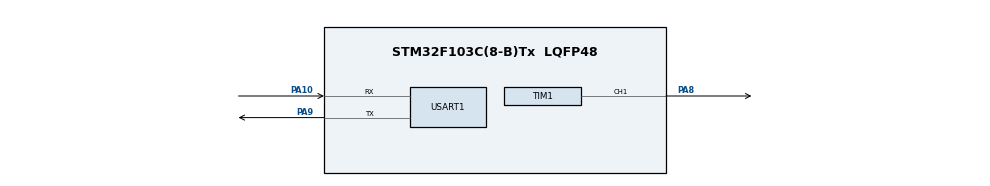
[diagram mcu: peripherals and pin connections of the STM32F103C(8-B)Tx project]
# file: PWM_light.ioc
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Mcu.Family=STM32F1
Mcu.Name=STM32F103C(8-B)Tx
Mcu.Package=LQFP48
NVIC.PriorityGroup=NVIC_PRIORITYGROUP_4
PA10.Mode=Asynchronous
PA10.Signal=USART1_RX
PA13.Mode=JTAG_4_pins
PA13.Signal=SYS_JTMS-SWDIO
PA14.Mode=JTAG_4_pins
PA14.Signal=SYS_JTCK-SWCLK
PA15.Mode=JTAG_4_pins
PA15.Signal=SYS_JTDI
PA8.Signal=S_TIM1_CH1
PA9.Mode=Asynchronous
PA9.Signal=USART1_TX
PB3.Mode=JTAG_4_pins
PB3.Signal=SYS_JTDO-TRACESWO
ProjectManager.HeapSize=0x200
ProjectManager.StackSize=0x400
ProjectManager.TargetToolchain=CMake
RCC.AHBCLKDivider=RCC_SYSCLK_DIV4
RCC.AHBFreq_Value=2000000
RCC.APB1Freq_Value=2000000
RCC.APB1TimFreq_Value=2000000
RCC.APB2Freq_Value=2000000
RCC.APB2TimFreq_Value=2000000
RCC.HCLKFreq_Value=2000000
RCC.USBFreq_Value=8000000
SH.S_TIM1_CH1.0=TIM1_CH1,PWM Generation1 CH1
TIM1.AutoReloadPreload=TIM_AUTORELOAD_PRELOAD_ENABLE
TIM1.Channel-PWM\ Generation1\ CH1=TIM_CHANNEL_1
TIM1.Period=40000
TIM1.Pulse-PWM\ Generation1\ CH1=30000
USART1.VirtualMode=VM_ASYNC
board=custom

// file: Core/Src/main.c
/* USER CODE BEGIN Header */
/**
  ******************************************************************************
  * @file           : main.c
  * @brief          : Main program body
  ******************************************************************************
  * @attention
  *
  * Copyright (c) 2026 STMicroelectronics.
  * All rights reserved.
  *
  * This software is licensed under terms that can be found in the LICENSE file
  * in the root directory of this software component.
  * If no LICENSE file comes with this software, it is provided AS-IS.
  *
  ******************************************************************************
  */
/* USER CODE END Header */
#include "main.h"
#include "tim.h"
#include "usart.h"
#include "gpio.h"

void SystemClock_Config(void);

int main(void)
{

  /* MCU Configuration--------------------------------------------------------*/

  /* Reset of all peripherals, Initializes the Flash interface and the Systick. */
  HAL_Init();

  /* Configure the system clock */
  SystemClock_Config();

  /* Initialize all configured peripherals */
  MX_GPIO_Init();
  MX_TIM1_Init();
  MX_USART1_UART_Init();
  /* USER CODE BEGIN 2 */
  HAL_TIM_PWM_Start(&htim1, TIM_CHANNEL_1);
  /* USER CODE END 2 */

  /* Infinite loop */
  /* USER CODE BEGIN WHILE */
  while (1)
  {
    for(int32_t duty=0;duty<=(int32_t)htim1.Init.Period;duty+=300)
    {
      __HAL_TIM_SET_COMPARE(&htim1,TIM_CHANNEL_1,duty);
      HAL_Delay(1);
    }
    for(int32_t duty=(int32_t)htim1.Init.Period;duty>=0;duty-=300)
    {
      __HAL_TIM_SET_COMPARE(&htim1,TIM_CHANNEL_1,duty);
      HAL_Delay(1);
    }
    /* USER CODE END WHILE */

  }
}

void SystemClock_Config(void)
{
  RCC_OscInitTypeDef RCC_OscInitStruct = {0};
  RCC_ClkInitTypeDef RCC_ClkInitStruct = {0};

  /** Initializes the RCC Oscillators according to the specified parameters
  * in the RCC_OscInitTypeDef structure.
  */
  RCC_OscInitStruct.OscillatorType = RCC_OSCILLATORTYPE_HSI;
  RCC_OscInitStruct.HSIState = RCC_HSI_ON;
  RCC_OscInitStruct.HSICalibrationValue = RCC_HSICALIBRATION_DEFAULT;
  RCC_OscInitStruct.PLL.PLLState = RCC_PLL_NONE;
  if (HAL_RCC_OscConfig(&RCC_OscInitStruct) != HAL_OK)
  {
    Error_Handler();
  }

  /** Initializes the CPU, AHB and APB buses clocks
  */
  RCC_ClkInitStruct.ClockType = RCC_CLOCKTYPE_HCLK|RCC_CLOCKTYPE_SYSCLK
                              |RCC_CLOCKTYPE_PCLK1|RCC_CLOCKTYPE_PCLK2;
  RCC_ClkInitStruct.SYSCLKSource = RCC_SYSCLKSOURCE_HSI;
  RCC_ClkInitStruct.AHBCLKDivider = RCC_SYSCLK_DIV4;
  RCC_ClkInitStruct.APB1CLKDivider = RCC_HCLK_DIV1;
  RCC_ClkInitStruct.APB2CLKDivider = RCC_HCLK_DIV1;

  if (HAL_RCC_ClockConfig(&RCC_ClkInitStruct, FLASH_LATENCY_0) != HAL_OK)
  {
    Error_Handler();
  }
}

void Error_Handler(void)
{
  __disable_irq();
  while (1)
  {
  }
}
